# ISP_CSI1B register map
Vendor: Texas Instruments
Peripheral module from a debugger description file (folder omap34xx).
Registers are 32-bit, read-write, reset 0x0 unless marked. A register's access mark holds for its fields unless they carry their own. Offsets are as the file gives them; lines under a group give offsets from that group; [hi:lo] are bit positions; {n}, {i} and the like mark numbered series; 'fields as' and 'values as' point back to an identical list; <NAME> marks a mode.

## ISP_CSI1B
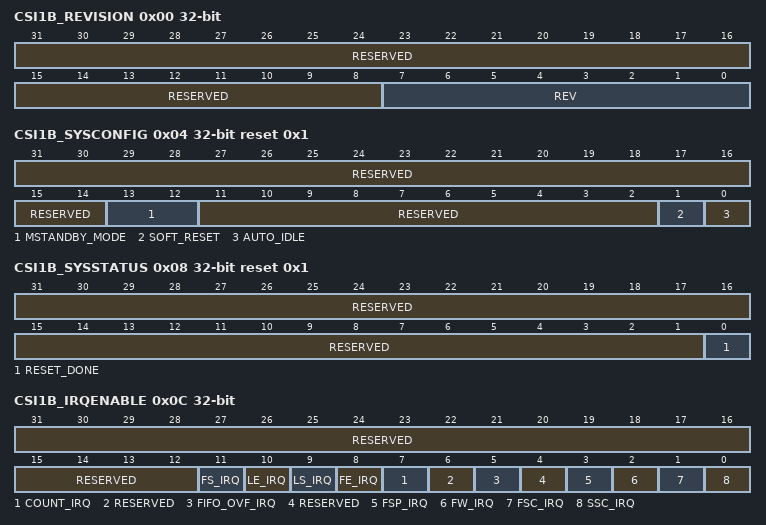
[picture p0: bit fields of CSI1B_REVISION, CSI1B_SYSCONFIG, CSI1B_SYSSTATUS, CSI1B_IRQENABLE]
0x00 CSI1B_REVISION ro (reset mask 0xFFFFFF00) — MODULE REVISION This register contains the IP revision code in binary coded digital. For example, we have: 0x01 = revision 0.1 and 0x21 = revision 2.1
  [31:8] RESERVED — Write 0s for future compatibility.Reads returns 0.
  [7:0] REV — IP revision [7:4] Major revision[3:0] Minor revision
0x04 CSI1B_SYSCONFIG reset 0x1 — SYSTEM CONFIGURATION REGISTER This register is the CSI1 system configuration register.
  [31:14] RESERVED — Write 0s for future compatibility.Reads returns 0.
  [13:12] MSTANDBY_MODE — Sets the behavior of the master port power management signals.
    0=Force-standby. Hardware signal is only asserted when the module is disabled.; 1=No-standby. Hardware signal is never asserted.; 2=Smart-standby: Hardware signal is asserted based on the activity of the module. The module tries to go to standby during the vertical blanking period.
  [11:2] RESERVED — Write 0s for future compatibility.Reads returns 0.
  [1] SOFT_RESET — Software reset. Set the bit to 1 to trigger a module reset. The bit is automatically reset by the HW. During reads return 0.
    0=Normal mode; 1=The module is reset
  [0] AUTO_IDLE — Internal interface clock gating strategy.
    0=Interface clock is free-running; 1=Automatic Interface clock gating strategy is applied based on the Interconnect interface activity
0x08 CSI1B_SYSSTATUS ro reset 0x1 — SYSTEM STATUS REGISTER This register provides status information about the module, excluding the interrupt status register.
  [31:1] RESERVED — Write 0s for future compatibility.Reads returns 0.
  [0] RESET_DONE — Internal reset monitoring
    0=Internal module reset is on going; 1=Reset completed
0x0C CSI1B_IRQENABLE — INTERRUPT ENABLE REGISTER
  [31:12] RESERVED — Write 0s for future compatibility.Reads returns 0.
  [11] FS_IRQ — Frame start sync code detection.
    0=Event is masked; 1=Event generates an interrupt when it occurs
  [10] LE_IRQ — Line end sync code detection.
    values as FS_IRQ
  [9] LS_IRQ — Line start sync code detection.
    values as FS_IRQ
  [8] FE_IRQ — Frame end sync code detection.
    values as FS_IRQ
  [7] COUNT_IRQ — Frame counter reached.
    values as FS_IRQ
  [6] RESERVED — Write 0s for future compatibility.Reads returns 0.
  [5] FIFO_OVF_IRQ — FIFO overflow error.
    values as FS_IRQ
  [4] RESERVED — Write 0s for future compatibility.Reads returns 0.
    values as FS_IRQ
  [3] FSP_IRQ — FSP error.
    values as FS_IRQ
  [2] FW_IRQ — Frame width error.
    values as FS_IRQ
  [1] FSC_IRQ — False sync code error.
    values as FS_IRQ
  [0] SSC_IRQ — Shifted sync code error. This interrupt cannot be triggered if the complex I/O is set in parallel mode (CSI1_CTRL.IO_OUT_SEL = 1).
    values as FS_IRQ
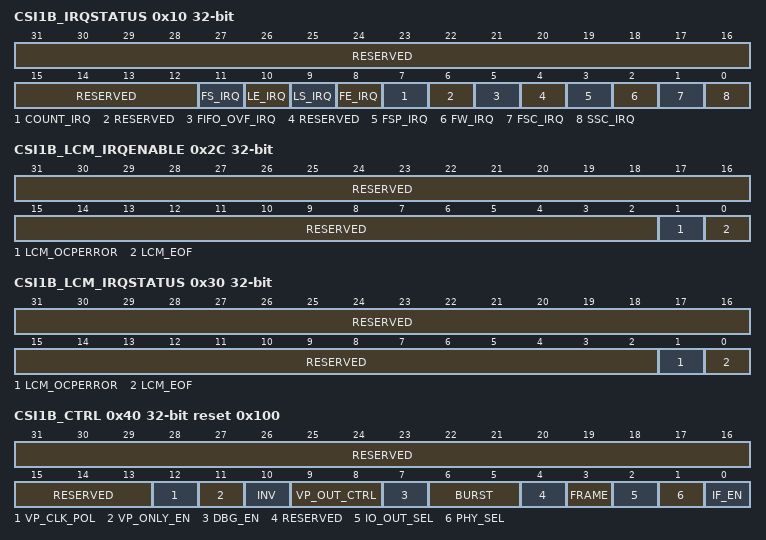
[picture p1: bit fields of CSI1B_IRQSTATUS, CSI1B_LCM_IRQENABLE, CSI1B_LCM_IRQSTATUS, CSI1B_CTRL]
0x10 CSI1B_IRQSTATUS access not given — INTERRUPT STATUS REGISTER
  [31:12] RESERVED rw — Write 0s for future compatibility.Reads returns 0.
  [11] FS_IRQ — Frame start sync code detection status. (access RW1toClr)
    0=READS: Event is false. WRITES: Status bit unchanged.; 1=READS: Event is true (pending). WRITES: Status bit is reset.
  [10] LE_IRQ — Line end sync code detection status. (access RW1toClr)
    values as FS_IRQ
  [9] LS_IRQ — Line start sync code detection status. (access RW1toClr)
    values as FS_IRQ
  [8] FE_IRQ — Frame end sync code detection status. (access RW1toClr)
    values as FS_IRQ
  [7] COUNT_IRQ — Frame counter reached status (access RW1toClr)
    values as FS_IRQ
  [6] RESERVED — Write 0s for future compatibility.Reads returns 0. (access RW1toClr)
  [5] FIFO_OVF_IRQ — FIFO overflow error status. (access RW1toClr)
    values as FS_IRQ
  [4] RESERVED — Write 0s for future compatibility.Reads returns 0. (access RW1toClr)
    values as FS_IRQ
  [3] FSP_IRQ — FSP error status. (access RW1toClr)
    values as FS_IRQ
  [2] FW_IRQ — Frame width error status. (access RW1toClr)
    values as FS_IRQ
  [1] FSC_IRQ — False sync code error status. (access RW1toClr)
    values as FS_IRQ
  [0] SSC_IRQ — Shifted sync code error status. (access RW1toClr)
    values as FS_IRQ
0x2C CSI1B_LCM_IRQENABLE — INTERRUPT ENABLE REGISTER - Memory channel This register regroups all the events related to the memory channel 2. The events related to memory channel trigger SINTERRUPTN[8]. The channel must be enabled for events to be generated on that channel.
  [31:2] RESERVED — Write 0s for future compatibility.Reads returns 0.
  [1] LCM_OCPERROR — An OCP error occurred on the master read port.
    values as CSI1B_IRQENABLE.FS_IRQ
  [0] LCM_EOF — Memory read channel - End of frame
    0=Event generates an interrupt when it occurs; 1=Event is masked
0x30 CSI1B_LCM_IRQSTATUS access not given — INTERRUPT STATUS REGISTER - Memory channel This register regroups all the events related to memory channel. The events related to memory channel trigger SINTERRUPTN[8]. The channel must be enabled for events to be generated on that channel.
  [31:2] RESERVED rw — Write 0s for future compatibility.Reads returns 0.
  [1] LCM_OCPERROR — An OCP error occurred on the master read port. (access RW 1toClr)
    0=READS: Event is true (pending). WRITES: Status bit is reset.; 1=READS: Event is false. WRITES: Status bit unchanged.
  [0] LCM_EOF — Memory read channel - End of frame (access RW 1toClr)
    values as CSI1B_IRQSTATUS.FS_IRQ
0x40 CSI1B_CTRL reset 0x100 — GLOBAL CONTROL REGISTER This register controls the CSI1 RECEIVER module. This register must not be modified dynamically (except IF_EN bit field).
  [31:13] RESERVED — Write 0s for future compatibility.Reads returns 0.
  [12] VP_CLK_POL — VP clock polarity
    0=The RECEIVER module writes the data on the VP on the pixel clock falling edge. The module connected to the VP must sample the data on the pixel clock rising edge.; 1=The RECEIVER module writes the data on the VP on the pixel clock raising edge. The module connected to the VP must sample the data on the pixel clock falling edge.
  [11] VP_ONLY_EN — VP only enable.
    0=The VP is enabled and the Interconnect master port are enabled; 1=The VP is enabled and the Interconnect master port is disabled. The embedded data and pixel data are output on the VP.
  [10] INV — Strobe/clock inversion control signal
    0=Not inverted; 1=Inverted
  [9:8] VP_OUT_CTRL — Video port output clock control. Sets the video port output clock as a function of the interface clock (OCPCLK).
    0=No division: video port clock = OCPCLK; 1=Division by 2: video port clock = OCPCLK/2; 2=Division by 3: video port clock = OCPCLK/3; 3=Division by 4: video port clock = OCPCLK/4
  [7] DBG_EN — Enables the debug mode.
    0=Disable; 1=Enable
  [6:5] BURST — Forces the write burst size used by the module. The write burst size must never exceed the output FIFO size. The output FIFO size can be read with the CSI1_GNQ.FIFODEPTH bit field.
    0=1x 64-bit burst = single request; 1=2x 64-bit bursts; 2=4x 64-bit bursts; 3=8x 64-bit bursts
  [4] RESERVED — Write 0s for future compatibility.Reads returns 0.
  [3] FRAME — Set the modality in which IF_EN works.
    0=When SW writes IF_EN = 0 the interface is disabled immediately; 1=When SW writes IF_EN = 1 the interface is disabled after the next FEC sync code
  [2] IO_OUT_SEL — I/O cell output mode selection.
    0=I/O output is serial: DATA, STROBE; 1=I/O output is parallel: DATA32, DATATOG, SYNTOG. Note that the SSC_IRQ error cannot be triggered in this configuration.
  [1] PHY_SEL — Physical layer protocol selection.
    0=Data/Clock physical layer; 1=Data/Strobe physical layer
  [0] IF_EN — Enables the physical interface to the module.
    0=The interface is disabled. If FRAME = 0, it is disabled immediately. If FRAME = 1, it is disabled on the next FEC sync code.; 1=The interface is enabled immediately, the data acquisition starts on the next FSC sync code. Writing 1 to this register when the current value is 0 has the effect to clear the output FIFO. The pixel data of the following frame is written in the PING buffer, that is, the CSI1_CTRL.PING_PONG bits are reset to 1 as well.
0x44 CSI1B_DBG wo — DEBUG REGISTER This register provides a way to debug the CSI1 RECEIVER module with no image sensor connected to the module. The debug mode is enabled by CSI1_CTRL.DBG_EN. Only full 32-bit values must be written.
  [31:0] DBG — 32-bit input value.
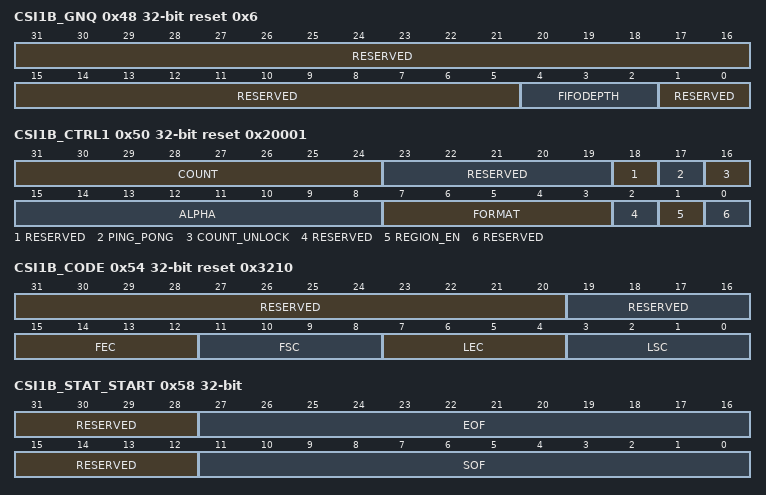
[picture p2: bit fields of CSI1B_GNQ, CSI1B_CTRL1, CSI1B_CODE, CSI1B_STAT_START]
0x48 CSI1B_GNQ ro reset 0x6 — GENERIC PARAMETER REGISTER This register provide a way to read the generic parameters used in the design.
  [31:5] RESERVED — Reads returns 0.
  [4:2] FIFODEPTH — Output FIFO size in multiple of 64 bits.
    0=2x 64 bits; 1=4x 64 bits; 2=8x 64 bits; 3=16x 64 bits; 4=32x 64 bits; 5=64x 64 bits
  [1:0] RESERVED — Read returns 2.
0x50 CSI1B_CTRL1 access per field reset 0x20001 — CONTROL REGISTER This register is shadowed: modifications are taken into account after the next FSC sync code.
  [31:24] COUNT rw — Sets the number of frame to acquire. Once the frame acquisition starts, the COUNT value is decremented after every frame. When COUNT reaches 0, the COUNT_IRQ interrupt is triggered and CHAN_EN is set to 0. Writes to this bit field are controlled by the COUNT_UNLOCK bit. COUNT can be overwritten dynamically with a new count value.' 0: Infinite number of frames (no count).1: 1 frame to acquire...255: 255 frames to acquire.
  [23:19] RESERVED rw — Write 0s for future compatibility.Reads returns 0.
  [18] RESERVED rw — Write 0s for future compatibility.Reads returns 0.
  [17] PING_PONG ro — Indicates whether the PING or PONG destination address (CSI1_DAT_PING_ADDR or CSI1_DAT_PONG_ADDR) was used to write the last frame. This bit field toggles after every FEC sync code.
    0=PING buffer; 1=PONG buffer
  [16] COUNT_UNLOCK wo — Unlock writes to the COUNT bit field.
    0=COUNT bit field is locked. Writes have no effect; 1=COUNT bit field is unlocked. Writes are possible.
  [15:8] ALPHA rw — Alpha value for RGB888 and RBG444.
  [7:3] FORMAT rw — Data format selection.
    0=YUV422 BIG ENDIAN; 1=YUV422 LITTLE ENDIAN; 2=YUV420; 3=YUV422 + VP or RAW8 + VP; 4=RGB444 + EXP16; 5=RGB565; 6=RGB888; 7=RGB888 + EXP32; 16=RAW8; 20=RAW10; 21=RAW10 + EXP16; 22=RAW10 + VP; 24=RAW12; 25=RAW12 + EXP16; 26=RAW12 + VP; 28=JPEG8 + FSP; 29=JPEG8; 30=RAW10 - RAW8 RAW10 data from sensor is right shifted to produce RAW8 before it is sent to memory
  [2] RESERVED rw — Write 0s for future compatibility.Reads returns 0.
  [1] REGION_EN rw — Enables the setting of regions of interest in the frame: SOF region, EOF region and DAT region.
    0=Disabled; 1=Enabled
  [0] RESERVED rw — Write 1 for future compatibility.Reads returns 1.
0x54 CSI1B_CODE reset 0x3210 — CODE REGISTER This register sets the codes that are used in the 32-bit synchronization codes to recognize frame start, frame end, line start and line end codes. The default values are usually not supposed to be modified. Updating this register with new codes under a flowing serial transmission causes unexpected results.
  [31:20] RESERVED — Write 0s for future compatibility.Reads returns 0.
  [19:16] RESERVED — Write 0s for future compatibility.Reads returns 0.
  [15:12] FEC — End sync code identifier. The sync code identifier is located between bits 0 to 3 in the 32-bit synchronization codes.
  [11:8] FSC — Start sync code identifier. The sync code identifier is located between bits 0 to 3 in the 32-bit synchronization codes.
  [7:4] LEC — End sync code identifier. The sync code identifier is located between bits 0 to 3 in the 32-bit synchronization codes.
  [3:0] LSC — Start sync code identifier. The sync code identifier is located between bits 0 to 3 in the 32-bit synchronization codes.
0x58 CSI1B_STAT_START — STATUS LINE START REGISTER This register is shadowed: modifications are taken into account after the next FSC sync code.
  [31:28] RESERVED — Write 0s for future compatibility.Reads returns 0.
  [27:16] EOF — Sets the vertical position of the EOF status lines in regards of the FSC sync code. From 0 to 4095.
  [15:12] RESERVED — Write 0s for future compatibility.Reads returns 0.
  [11:0] SOF — Sets the vertical position of the EOF status lines in regards of the FSC sync code. Should always be 0.
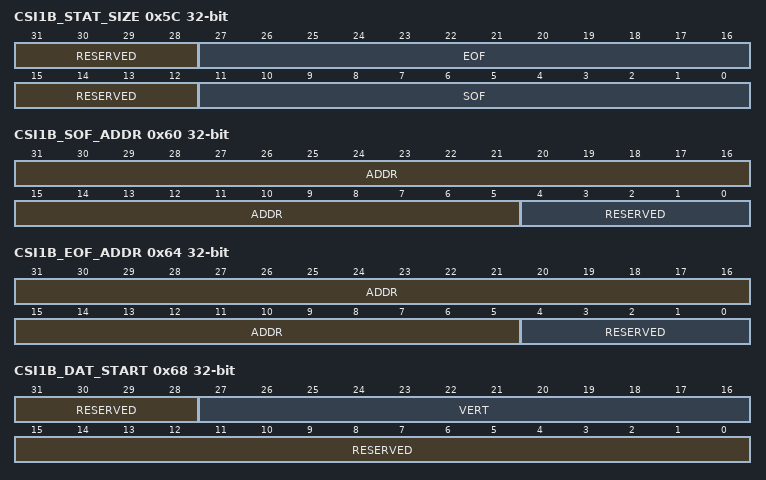
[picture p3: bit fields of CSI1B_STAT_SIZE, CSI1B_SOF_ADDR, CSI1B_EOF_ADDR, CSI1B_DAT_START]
0x5C CSI1B_STAT_SIZE — STATUS LINE SIZE REGISTER This register is shadowed: modifications are taken into account after the next FSC sync code.
  [31:28] RESERVED — Write 0s for future compatibility.Reads returns 0.
  [27:16] EOF — Sets the number of EOF status linesFrom 0 to 4095
  [15:12] RESERVED — Write 0s for future compatibility.Reads returns 0.
  [11:0] SOF — Sets the number of SOF status line(s)From 0 to 4095
0x60 CSI1B_SOF_ADDR — SOF STATUS LINE MEM ADDRESS REGISTER This register sets the 32-bit memory address where the SOF data are stored. Note that the 5 LSBs are ignored: the address should be aligned on a 32-byte boundary. This register is shadowed: modifications are taken into account after the next FSC sync code.
  [31:5] ADDR — 27 most significant bits of the 32-bit address.
  [4:0] RESERVED — 5 least significant bits of the 32-bit address. Write 0s for future compatibility.Reads returns 0.
0x64 CSI1B_EOF_ADDR — EOF STATUS LINE MEM ADDRESS REGISTER This register sets the 32-bit memory address where the EOF data are stored. Note that the 5 LSBs are ignored: the address should be aligned on a 32-byte boundary. This register is shadowed: modifications are taken into account after the next FSC sync code.
  fields as CSI1B_SOF_ADDR
0x68 CSI1B_DAT_START — DATA START REGISTER This register is shadowed: modifications are taken into account after the next FSC sync code.
  [31:28] RESERVED — Write 0s for future compatibility.Reads returns 0.
  [27:16] VERT — Sets the vertical position of the data in regards of the FSC sync code. From 0 to 4095 lines.
  [15:0] RESERVED — Write 0s for future compatibility.Reads returns 0.
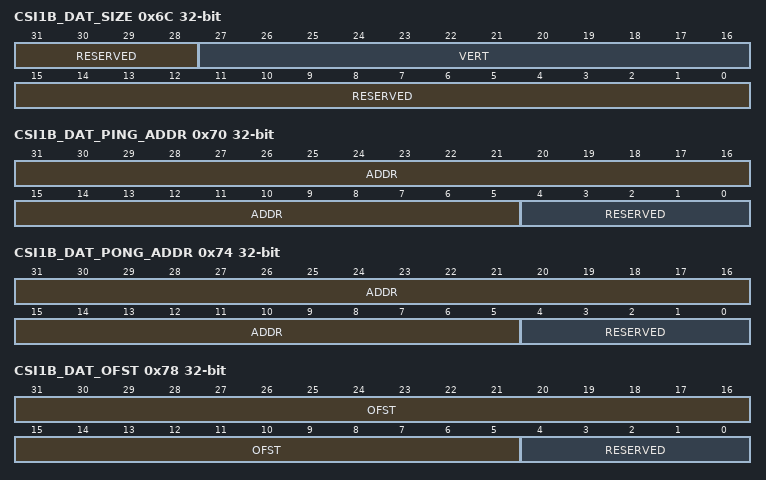
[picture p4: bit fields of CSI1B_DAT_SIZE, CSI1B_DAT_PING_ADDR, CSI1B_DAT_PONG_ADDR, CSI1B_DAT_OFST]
0x6C CSI1B_DAT_SIZE — DATA SIZE REGISTER This register is shadowed: modifications are taken into account after the next FSC sync code.
  [31:28] RESERVED — Write 0s for future compatibility.Reads returns 0.
  [27:16] VERT — Sets the vertical size of the data window. From 0 to 4095 lines. If VERT = '0', no data is output.
  [15:0] RESERVED — Write 0s for future compatibility.Reads returns 0.
0x70 CSI1B_DAT_PING_ADDR — DATA MEM PING ADDRESS REGISTER This register sets the 32-bit memory address where the pixel data are stored. The destination is double buffered: this register sets the PING address. Double buffering is enabled when the addresses CSI1_DAT_PING_ADDR and CSI1_DAT_PONG_ADDR are different. Note that the 5 LSBs are ignored: the address should be aligned on a 32-byte boundary. This register is shadowed: modifications are taken into account after the next FSC sync code.
  fields as CSI1B_SOF_ADDR
0x74 CSI1B_DAT_PONG_ADDR — DATA MEM PONG ADDRESS REGISTER - LOG CHAN 0 This register sets the 32-bit memory address where the pixel data are stored. The destination is double buffered: this register sets the PONG address. Double buffering is enabled when the addresses CSI1_DAT_PING_ADDR andCSI1_DAT_PONG_ADDR are different. Note that the 5 LSBs are ignored: the address should be aligned on a 32-byte boundary. This register is shadowed: modifications are taken into account after the next FSC sync code.
  fields as CSI1B_SOF_ADDR
0x78 CSI1B_DAT_OFST — DATA MEM ADDRESS OFFSET REGISTER This register sets the offset, which is applied on the destination address after each line is written to memory. This register applies for both CSI1_DAT_PING_ADDR and CSI1_DAT_PONG_ADDR. For example, it enables to perform 2D data transfers of the pixel data into a frame buffer. In such case, the pixel data and frame buffer data must have the same data format. Note that the 5 LSBs are ignored: the offset must be a multiple of 32 bytes. The usage of this register is limited to the following data formats: YUV422 LITTLE ENDIAN, YUV422 BIG ENDIAN, RGB565, RGB444 + EXP16, RGB888 + EXP32. This register is shadowed: modifications are taken into account after the next FSC sync code.
  [31:5] OFST — Line offset programmed in bytes. If OFST = 0, the data is written contiguously in memory. Otherwise, OFST sets the destination offset between the first pixel of the previous line and the first pixel of the current line.
  [4:0] RESERVED — Write 0s for future compatibility.Reads returns 0.
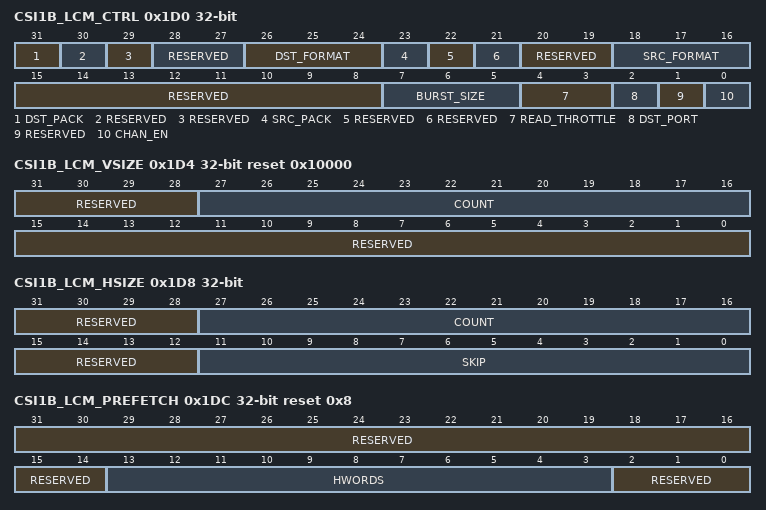
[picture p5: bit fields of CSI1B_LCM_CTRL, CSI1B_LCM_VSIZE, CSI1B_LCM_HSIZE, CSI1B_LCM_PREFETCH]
0x1D0 CSI1B_LCM_CTRL — Control register for the memory channel. It defines the data format of the source frame stored in memory and how this frame is processed.
  [31] DST_PACK — Data is packed before it is sent to memory.
    0=Enabled; 1=Disabled
  [30] RESERVED — Write 0s for future compatibility.Reads returns 0.
  [29] RESERVED — Write 0s for future compatibility.Reads returns 0.
  [28:27] RESERVED — Write 0s for future compatibility.Reads returns 0.
  [26:24] DST_FORMAT — Output format selection.Not every combination between input and output formats are possible. Check the specification for allowed modes.
    2=RAW8; 3=RAW10; 4=RAW12
  [23] SRC_PACK — Data stored in memory is packed and must be unpacked.
    0=Enabled; 1=Disabled
  [22] RESERVED — Write 0s for future compatibility.Reads returns 0.
  [21] RESERVED — Write 0s for future compatibility.Reads returns 0.
  [20:19] RESERVED — Write 0s for future compatibility.Reads returns 0.
  [18:16] SRC_FORMAT — Data format of the data stored in memory.As there is no header embedded in the data sent to memory, users are responsible of choosing the proper format.
    2=RAW8; 3=RAW10; 4=RAW12
  [15:8] RESERVED — Write 0s for future compatibility.Reads returns 0.
  [7:5] BURST_SIZE — Defines the burst size of the master read port
    0=1x 64-bit burst = single request; 1=2x 64-bit bursts; 2=4x 64-bit bursts; 3=8x 64-bit bursts; 4=16x 64-bit bursts; 5=32x 64-bit bursts
  [4:3] READ_THROTTLE — Limit maximum data read speed for memory to memory operation
  [2] DST_PORT — Select the destination port
    0=Data is sent to memory; 1=Data is sent to video port, it is always sent without compression or packing
  [1] RESERVED — Write 0s for future compatibility.Reads returns 0.
  [0] CHAN_EN — Enables the read from memory channel.Before enabling the memory read channel SW must:- disable the physical interface using the IF_EN bit- wait until disabling of the physical interface is effective (depends on the FRAME bit) Read from memory starts as soon as this bit is set, therefore all CSI1_LCM_x registers must be configured correctly before.This bit is cleared by HW at the end of the frame.
    0=Disabled; 1=Enabled
0x1D4 CSI1B_LCM_VSIZE reset 0x10000 — Memory channel vertical framing register
  [31:28] RESERVED — Write 0s for future compatibility.Reads returns 0.
  [27:16] COUNT — Defines the line count to be read from memory. From 1 to 4095 lines.
  [15:0] RESERVED — Write 0s for future compatibility.Reads returns 0.
0x1D8 CSI1B_LCM_HSIZE — Memory read channel horizontal framing register.
  [31:28] RESERVED — Write 0s for future compatibility.Reads returns 0.
  [27:16] COUNT — Horizontal count of pixels to output after the skipped pixels.Valid values: 1-4095.
  [15:12] RESERVED — Write 0s for future compatibility.Reads returns 0.
  [11:0] SKIP — Horizontal count of pixels to skip after the start of the line.Valid values: 0-4095.0 disables pixel skipping
0x1DC CSI1B_LCM_PREFETCH reset 0x8 — This register defines the amount of data to be fetched from memory. Is must be consistent with the CSI1_LCM_HSIZE register (check programing model)
  [31:14] RESERVED — Write 0s for future compatibility.Reads returns 0.
  [13:3] HWORDS — 64 bit words to read from memory for each line of the image.Possible values 1..2047
  [2:0] RESERVED — Write 0s for future compatibility.Reads returns 0.
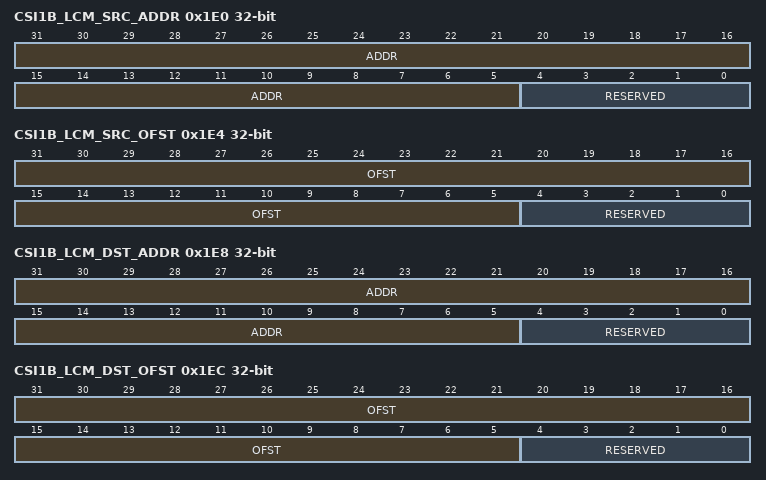
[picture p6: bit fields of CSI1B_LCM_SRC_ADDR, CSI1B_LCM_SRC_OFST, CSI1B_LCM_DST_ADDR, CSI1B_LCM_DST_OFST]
0x1E0 CSI1B_LCM_SRC_ADDR — Memory channel source address register This register sets the 32-bit memory address where the pixel data are stored. Note that the 5 LSBs are ignored: the address should be aligned on a 32-byte boundary.
  fields as CSI1B_SOF_ADDR
0x1E4 CSI1B_LCM_SRC_OFST — Memory channel source offset register. This register sets the offset, which is applied on the source address after each line is read from memory. For example, it enables to perform 2D data transfers of the pixel data from a frame buffer. In such case, the pixel data and frame buffer data must have the same data format. Note that the 5 LSBs are ignored: the offset must be a multiple of 32 bytes.
  [31:5] OFST — Line offset programmed in bytes. If OFST = 0, the data is read contiguously from memory. Otherwise, OFST sets the source offset between the first pixel of the previous line and the first pixel of the current line.
  [4:0] RESERVED — Write 0s for future compatibility.Reads returns 0.
0x1E8 CSI1B_LCM_DST_ADDR — Memory channel destination address. This register sets the 32-bit memory address where the pixel data are stored. Note that the 5 LSBs are ignored: the address should be aligned on a 32-byte boundary.
  fields as CSI1B_SOF_ADDR
0x1EC CSI1B_LCM_DST_OFST — Memory channel destination offset register. This register sets the offset, which is applied on the destination address after each line is written to memory. For example, it enables to perform 2D data transfers of the pixel data into a frame buffer. In such case, the pixel data and frame buffer data must have the same data format. Note that the 5 LSBs are ignored: the offset must be a multiple of 32 bytes.
  [31:5] OFST — Line offset programmed in bytes. If OFST = 0, the data is written contiguously to memory if possible. At the end of a line only full 32 bit words are written, creating eventually gaps at the end of lines. Otherwise, OFST sets the destination offset between the first pixel of the previous line and the first pixel of the current line.
  [4:0] RESERVED — Write 0s for future compatibility.Reads returns 0.
